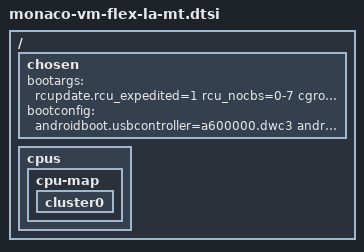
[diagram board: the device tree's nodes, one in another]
#include "monaco-vm-la-mt.dtsi"

/ {
	  chosen {
		bootargs = "rcupdate.rcu_expedited=1 rcu_nocbs=0-7 cgroup.memory=nokmem,nosocket kpti=0 arm64.nopauth kasan=off msm_show_resume_irq.debug_mask=1";
		bootconfig = "androidboot.usbcontroller=a600000.dwc3 androidboot.fstab_suffix=gen4.qcom androidboot.dtbo_idx=8";
	};

	cpus {
		/delete-node/ opp-table1;
		/delete-node/ cpu@2;
		/delete-node/ cpu@3;
		/delete-node/ cpu@4;
		/delete-node/ cpu@5;
		/delete-node/ cpu@6;
		/delete-node/ cpu@7;

		cpu-map {
			cluster0 {
				/delete-node/ core2;
				/delete-node/ core3;
			};

			/delete-node/ cluster1;
		};
	};
};
